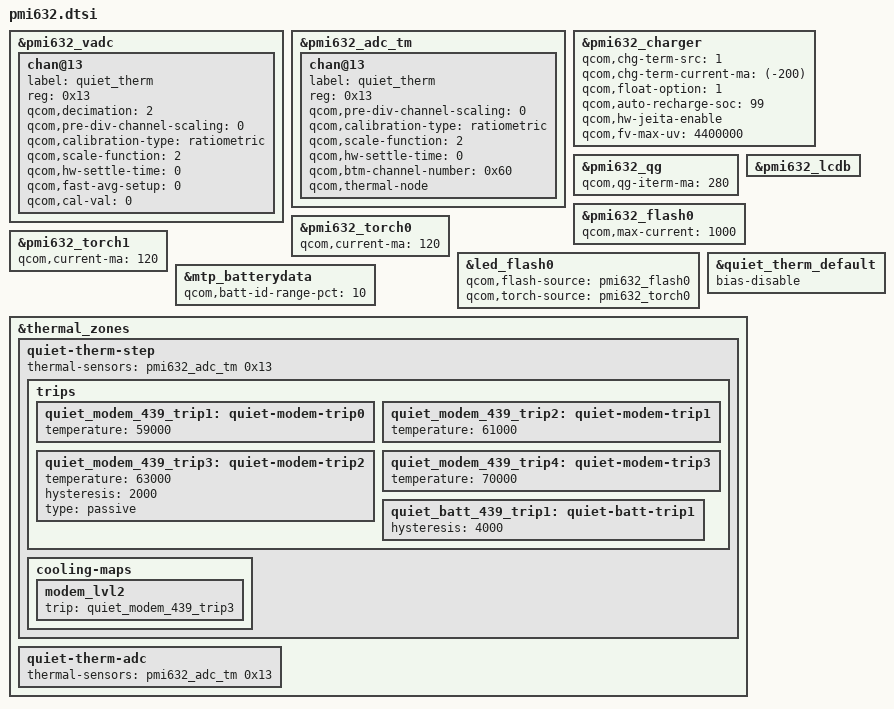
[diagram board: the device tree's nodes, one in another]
/* From stock pmi632.dtsi */
&pmi632_vadc {
	/* WARNING: Redefine node */
	/delete-node/ chan@53;
	chan@13 {
		label = "quiet_therm";
		reg = <0x13>;
		qcom,decimation = <2>;
		qcom,pre-div-channel-scaling = <0>;
		qcom,calibration-type = "ratiometric";
		qcom,scale-function = <2>;
		qcom,hw-settle-time = <0>;
		qcom,fast-avg-setup = <0>;
		qcom,cal-val = <0>;
	};
};

&pmi632_adc_tm {
	/* WARNING: Redefine node */
	/delete-node/ chan@53;
	chan@13 {
		label = "quiet_therm";
		reg = <0x13>;
		qcom,pre-div-channel-scaling = <0>;
		qcom,calibration-type = "ratiometric";
		qcom,scale-function = <2>;
		qcom,hw-settle-time = <0>;
		qcom,btm-channel-number = <0x60>;
		qcom,thermal-node;
	};
};

&pmi632_charger {
	qcom,chg-term-src = <1>;
	qcom,chg-term-current-ma = <(-200)>;
	qcom,float-option = <1>;
	qcom,auto-recharge-soc = <99>;
	/delete-property/ qcom,sw-jeita-enable;
	qcom,hw-jeita-enable;
	qcom,fv-max-uv = <4400000>;
};

&pmi632_qg {
	qcom,qg-iterm-ma = <280>;
};

&pmi632_lcdb {
	/delete-property/ qcom,voltage-step-ramp;
};

&pmi632_flash0 {
	qcom,max-current = <1000>;
};

&pmi632_torch0 {
	qcom,current-ma = <120>;
};

&pmi632_torch1 {
	qcom,current-ma = <120>;
};

&led_flash0 {
	qcom,flash-source = <&pmi632_flash0>;
	qcom,torch-source = <&pmi632_torch0>;
};

/* From stock sdm439-pmi632.dtsi */
&mtp_batterydata {
	qcom,batt-id-range-pct = <10>;
	/delete-node/ qcom,ascent_3450mah;
	/delete-node/ qcom,mlp356477_2800mah;
	#include "batterydata/Peony-GY-4000mah-51kohm.dtsi"
	#include "batterydata/Peony-NVT-4000mah-41kohm.dtsi"
	#include "batterydata/Peony-SWD-4000mah-78kohm.dtsi"
	#include "batterydata/Peony-Default-4000mah-78kohm.dtsi"
};

&quiet_therm_default {
	bias-disable;
};

&thermal_zones {
	quiet-therm-step {
		thermal-sensors = <&pmi632_adc_tm 0x13>;
		/delete-property/ wake-capable-sensor;

		trips {
			/delete-node/ quiet-bt-trp6-mdm-trp3;
			/delete-node/ quiet-batt-trip7;

			quiet_modem_439_trip1: quiet-modem-trip0 {
				temperature = <59000>;
			};
			quiet_modem_439_trip2: quiet-modem-trip1 {
				temperature = <61000>;
			};
			quiet_modem_439_trip3: quiet-modem-trip2 {
				temperature = <63000>;
				hysteresis = <2000>;
				type = "passive";
			};
			quiet_modem_439_trip4: quiet-modem-trip3 {
				temperature = <70000>;
			};
			quiet_batt_439_trip1: quiet-batt-trip1 {
				hysteresis = <4000>;
			};
		};

		cooling-maps {
			modem_lvl2 {
				trip = <&quiet_modem_439_trip3>;
			};
			/delete-node/ battery_lvl6;
			/delete-node/ battery_lvl7;
		};
	};

	quiet-therm-adc {
		thermal-sensors = <&pmi632_adc_tm 0x13>;
		/delete-property/ wake-capable-sensor;
	};
};
